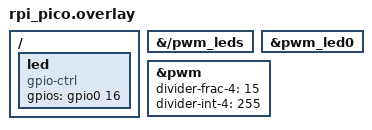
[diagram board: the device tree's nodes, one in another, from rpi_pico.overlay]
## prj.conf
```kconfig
CONFIG_GPIO=y
CONFIG_STDOUT_CONSOLE=y
CONFIG_PRINTK=y
CONFIG_PWM=y
CONFIG_LOG=y
CONFIG_LOG_PRINTK=y
CONFIG_LOG_MODE_IMMEDIATE=y
CONFIG_PWM_LOG_LEVEL_DBG=y
```

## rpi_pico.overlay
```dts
/ {
    led: led {
        compatible = "gpio-ctrl";
        gpios = <&gpio0 16 0x0>;
    };

};


/* The rpi_pico/rp2040/w doesn't have a pwm. */
/* Use the HAS_DT_PWM defined by the based board to identify when this overlay is valid */
// #if HAS_DT_PWM_LED

&{/pwm_leds} {
	status = "okay";
};

&pwm_led0 {
	status = "okay";
};

&pwm {
	status = "okay";
	divider-frac-4 = <15>;
	divider-int-4 = <255>;
};

// #endif
```

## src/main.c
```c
/*
 * Copyright (c) 2023 Libre Solar Technologies GmbH
 *
 * SPDX-License-Identifier: Apache-2.0
 */

#include <stdio.h>

#include <zephyr/devicetree.h>
#include <zephyr/device.h>
#include <zephyr/drivers/gpio.h>
#include <zephyr/drivers/pwm.h>
#include <zephyr/kernel.h>
#include <zephyr/sys/printk.h>


//LED_PWM
static const struct pwm_dt_spec pwm_led0 = PWM_DT_SPEC_GET(DT_ALIAS(pwm_led0));

// #define MIN_PERIOD PWM_SEC(1U) / 128U
// #define MAX_PERIOD PWM_SEC(1U)
#define MIN_PERIOD PWM_NSEC(7812500)
#define MAX_PERIOD PWM_NSEC(125000000)

int main(void)
{
	//LED--------------------------------------------------------------------------------------
	//static const struct gpio_dt_spec led_dev = GPIO_DT_SPEC_GET(DT_NODELABEL(led), gpios);
	//gpio_pin_configure_dt(&led_dev, GPIO_OUTPUT_ACTIVE);
	
	//LED_PWM----------------------------------------------------
	uint32_t max_period;
	uint32_t period;
	uint8_t dir = 0U;
	int ret;

	printk("PWM-based blinky\n");

	if (!pwm_is_ready_dt(&pwm_led0)) {
		printk("Error: PWM device %s is not ready\n",
		       pwm_led0.dev->name);
		return 0;
	}

	/*
	 * In case the default MAX_PERIOD value cannot be set for
	 * some PWM hardware, decrease its value until it can.
	 *
	 * Keep its value at least MIN_PERIOD * 4 to make sure
	 * the sample changes frequency at least once.
	 */
	printk("Calibrating for channel %d...\n", pwm_led0.channel);
	max_period = MAX_PERIOD;
	while (pwm_set_dt(&pwm_led0, max_period, max_period / 2U)) {
		max_period /= 2U;
		if (max_period < (4U * MIN_PERIOD)) {
			printk("Error: PWM device "
			       "does not support a period at least %lu\n",
			       4U * MIN_PERIOD);
			return 0;
		}
	}

	printk("Done calibrating; maximum/minimum periods %u/%lu nsec\n",
	       max_period, MIN_PERIOD);

	period = max_period;

    while(1){
        //LED-------------------------------------------------------------
        printk("nel main\n");
        //k_msleep(500);
        //gpio_pin_toggle_dt(&led_dev);
		
		//LED_PWM
		ret = pwm_set_dt(&pwm_led0, period, period / 2U);
		if (ret) {
			printk("Error %d: failed to set pulse width\n", ret);
			return 0;
		}

		period = dir ? (period * 2U) : (period / 2U);
		if (period > max_period) {
			period = max_period / 2U;
			dir = 0U;
		} else if (period < MIN_PERIOD) {
			period = MIN_PERIOD * 2U;
			dir = 1U;
		}

		k_sleep(K_SECONDS(2));
    }
	return 0;
}
```
